AUTOSAR XML (schema 4-2-2)
package /ComponentTypes
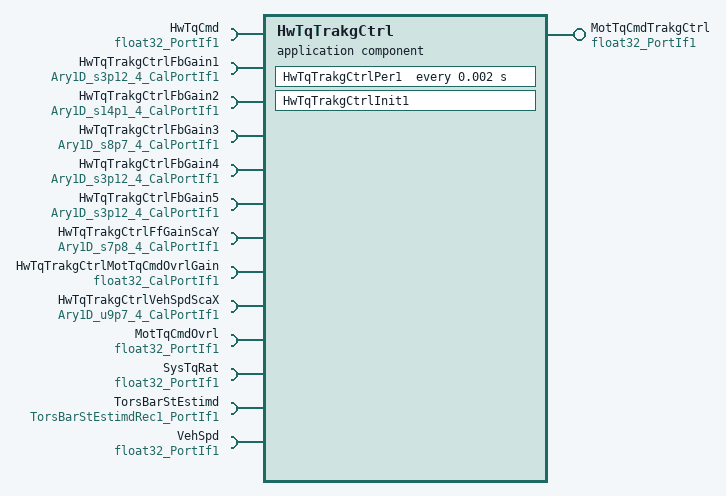
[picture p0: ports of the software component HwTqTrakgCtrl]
  application sw component type HwTqTrakgCtrl
    provide port MotTqCmdTrakgCtrl: nonqueued-sender-com-spec{data-element=Val, init-value=0}, provided-interface=float32_PortIf1
    13 x require port:
      HwTqCmd: nonqueued-receiver-com-spec{data-element=Val, filter=data-filter-type=ALWAYS, init-value=1}, required-interface=float32_PortIf1
      HwTqTrakgCtrlFbGain1: parameter-require-com-spec{init-value=[0, 0, 0, 0], parameter=Ary1D}, required-interface=Ary1D_s3p12_4_CalPortIf1
      HwTqTrakgCtrlFbGain2: parameter-require-com-spec{init-value=[0, 0, 0, 0], parameter=Ary1D}, required-interface=Ary1D_s14p1_4_CalPortIf1
      HwTqTrakgCtrlFbGain3: parameter-require-com-spec{init-value=[0, 0, 0, 0], parameter=Ary1D}, required-interface=Ary1D_s8p7_4_CalPortIf1
      HwTqTrakgCtrlFbGain4: parameter-require-com-spec{init-value=[0, 0, 0, 0], parameter=Ary1D}, required-interface=Ary1D_s3p12_4_CalPortIf1
      HwTqTrakgCtrlFbGain5: parameter-require-com-spec{init-value=[0, 0, 0, 0], parameter=Ary1D}, required-interface=Ary1D_s3p12_4_CalPortIf1
      HwTqTrakgCtrlFfGainScaY: parameter-require-com-spec{init-value=[0, 0, 0, 0], parameter=Ary1D}, required-interface=Ary1D_s7p8_4_CalPortIf1
      HwTqTrakgCtrlMotTqCmdOvrlGain: parameter-require-com-spec{init-value=0, parameter=Val}, required-interface=float32_CalPortIf1
      HwTqTrakgCtrlVehSpdScaX: parameter-require-com-spec{init-value=[0, 1280, 2560, 25600], parameter=Ary1D}, required-interface=Ary1D_u9p7_4_CalPortIf1
      MotTqCmdOvrl: nonqueued-receiver-com-spec{data-element=Val, filter=data-filter-type=ALWAYS, init-value=0}, required-interface=float32_PortIf1
      SysTqRat: nonqueued-receiver-com-spec{data-element=Val, filter=data-filter-type=ALWAYS, init-value=10}, required-interface=float32_PortIf1
      TorsBarStEstimd: nonqueued-receiver-com-spec{data-element=Rec, filter=data-filter-type=ALWAYS, init-value=fields=[ElementConstant:10, ElementConstant_1:0.95, ElementConstant_2:1000, ElementConstant_3:20, ElementConstant_4:100]}, required-interface=TorsBarStEstimdRec1_PortIf1
      VehSpd: nonqueued-receiver-com-spec{data-element=Val, filter=data-filter-type=ALWAYS, init-value=0}, required-interface=float32_PortIf1
    behavior HwTqTrakgCtrl_InternalBehavior
      init event HwTqTrakgCtrl_InitEvent: start-on-event=HwTqTrakgCtrlInit1
      timing event TMT_HwTqTrakgCtrlPer1: start-on-event=HwTqTrakgCtrlPer1, period=0.002
      port-api-options:
        enable-take-address=false, error-handling=NO-TRANSFORMER-ERROR-HANDLING, indirect-api=false, port=HwTqCmd
        enable-take-address=false, error-handling=NO-TRANSFORMER-ERROR-HANDLING, indirect-api=false, port=HwTqTrakgCtrlFbGain{1..5}
        enable-take-address=false, error-handling=NO-TRANSFORMER-ERROR-HANDLING, indirect-api=false, port=HwTqTrakgCtrlFfGainScaY
        enable-take-address=false, error-handling=NO-TRANSFORMER-ERROR-HANDLING, indirect-api=false, port=HwTqTrakgCtrlMotTqCmdOvrlGain
        enable-take-address=false, error-handling=NO-TRANSFORMER-ERROR-HANDLING, indirect-api=false, port=HwTqTrakgCtrlVehSpdScaX
        enable-take-address=false, error-handling=NO-TRANSFORMER-ERROR-HANDLING, indirect-api=false, port=MotTqCmdOvrl
        enable-take-address=false, error-handling=NO-TRANSFORMER-ERROR-HANDLING, indirect-api=false, port=MotTqCmdTrakgCtrl
        enable-take-address=false, error-handling=NO-TRANSFORMER-ERROR-HANDLING, indirect-api=false, port=SysTqRat
        enable-take-address=false, error-handling=NO-TRANSFORMER-ERROR-HANDLING, indirect-api=false, port=TorsBarStEstimd
        enable-take-address=false, error-handling=NO-TRANSFORMER-ERROR-HANDLING, indirect-api=false, port=VehSpd
      runnable HwTqTrakgCtrlInit1
      runnable HwTqTrakgCtrlPer1
        data-receive-point-by-arguments:
          5 x access:
            REC_HwTqCmd_Val: accessed-variable=HwTqCmd.Val
            REC_MotTqCmdOvrl_Val: accessed-variable=MotTqCmdOvrl.Val
            REC_SysTqRat_Val: accessed-variable=SysTqRat.Val
            REC_TorsBarStEstimd_Rec: accessed-variable=TorsBarStEstimd.Rec
            REC_VehSpd_Val: accessed-variable=VehSpd.Val
        data-send-points:
          access SEND_MotTqCmdTrakgCtrl_Val: accessed-variable=MotTqCmdTrakgCtrl.Val
  swc implementation HwTqTrakgCtrl_Implementation: behavior=HwTqTrakgCtrl_InternalBehavior
    code-descriptors:
      code Default: artifact-descriptors=autosar-engineering-object={short-label=Default, category=SWSRC}
